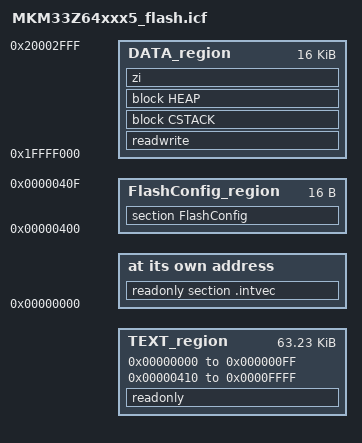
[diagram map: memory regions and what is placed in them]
/* Linker file for IAR ANSI C/C++ Compiler for ARM */

define symbol m_interrupts_start       = 0x00000000;
define symbol m_interrupts_end         = 0x000000FF;

define symbol m_text_start             = 0x00000410;
define symbol m_text_end               = 0x0000FFFF;

define symbol m_data_start             = 0x1FFFF000;
define symbol m_data_end               = 0x20002FFF;

define symbol FlashConfig_start__      = 0x00000400;
define symbol FlashConfig_end__        = 0x0000040F;

/* Sizes */
define symbol __size_cstack__          = 0x0400;
define symbol __size_heap__            = 0x0400;

define exported symbol __VECTOR_TABLE  = m_interrupts_start;

define memory mem with size = 4G;
define region FlashConfig_region = mem:[from FlashConfig_start__ to FlashConfig_end__];
define region TEXT_region = mem:[from m_interrupts_start to m_interrupts_end]
                          | mem:[from m_text_start to m_text_end];
define region DATA_region = mem:[from m_data_start to m_data_end];

define block CSTACK    with alignment = 8, size = __size_cstack__   { };
define block HEAP      with alignment = 8, size = __size_heap__     { };

initialize by copy { readwrite, section .textrw };
do not initialize  { section .noinit };

place at address mem: m_interrupts_start    { readonly section .intvec };
place in FlashConfig_region                 { section FlashConfig };
place in TEXT_region                        { readonly };
place in DATA_region                        { readwrite, block CSTACK, block HEAP };
place in DATA_region                        { zi };
